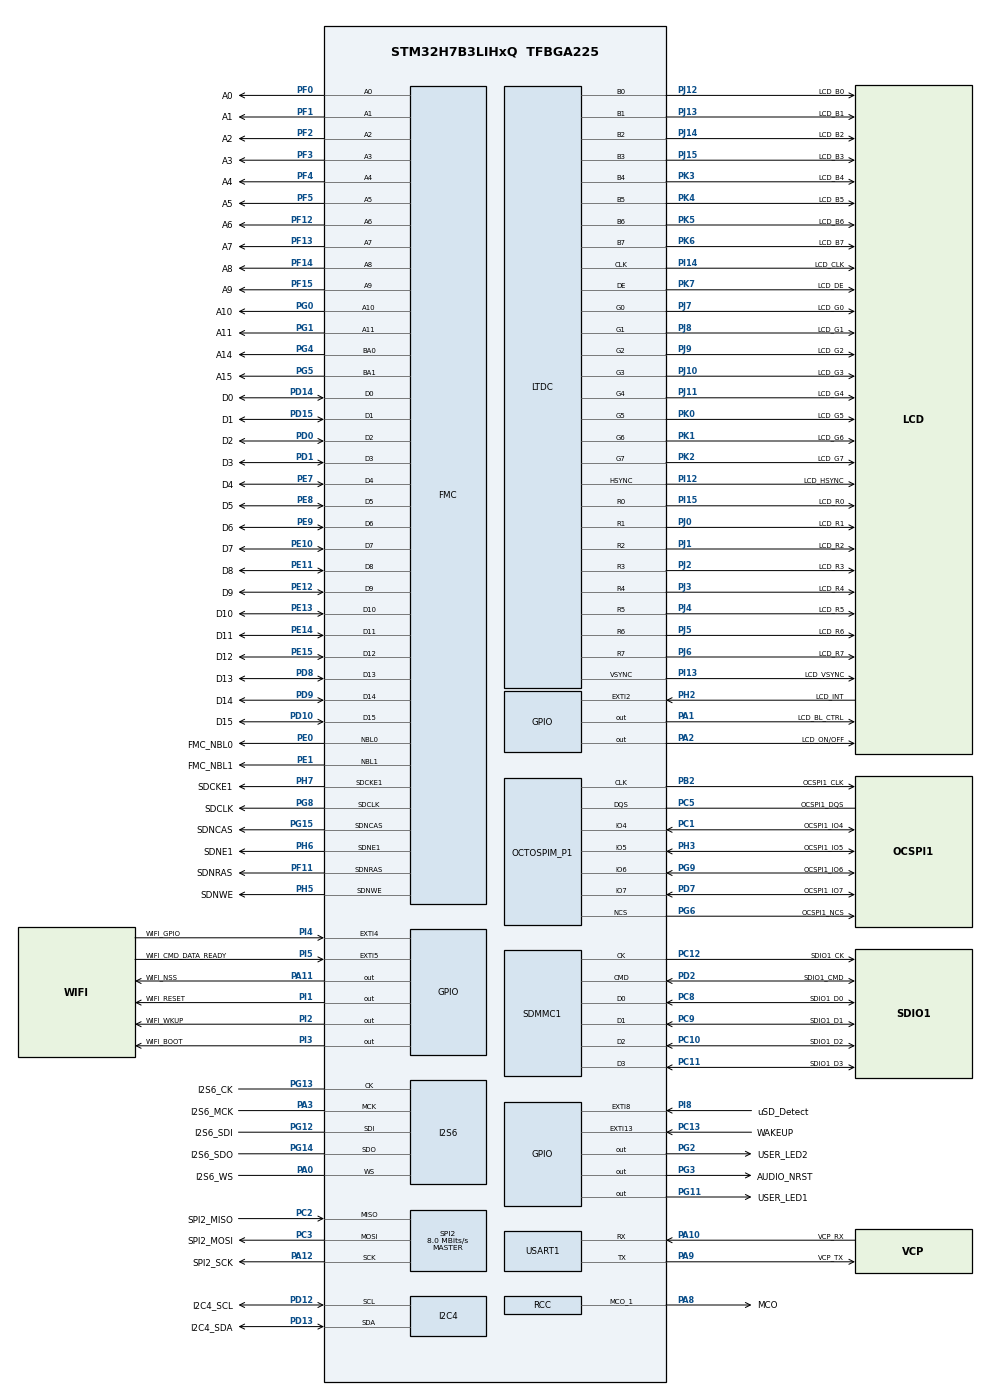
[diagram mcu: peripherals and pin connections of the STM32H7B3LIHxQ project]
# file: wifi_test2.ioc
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I2C4.Timing=0xC010151E
I2S6.ErrorAudioFreq=0.52 %
I2S6.FullDuplexMode=I2S_MODE_MASTER_FD
I2S6.Instance=SPI$Index
I2S6.RealAudioFreq=8.042 KHz
I2S6.VirtualMode=I2S_MODE_MASTER
LTDC.ActiveH=272
LTDC.ActiveW=480
LTDC.HBP=43
LTDC.HFP=8
LTDC.HSync=1
LTDC.VBP=12
LTDC.VFP=4
LTDC.VSync=10
Mcu.Family=STM32H7
Mcu.Name=STM32H7B3LIHxQ
Mcu.Package=TFBGA225
NVIC.PriorityGroup=NVIC_PRIORITYGROUP_4
OCTOSPI1.MemoryType=HAL_OSPI_MEMTYPE_MACRONIX
PA0.GPIO_Label=I2S6_WS
PA0.Mode=Full_Duplex_Master
PA0.Signal=I2S6_WS
PA1.GPIO_Label=LCD_BL_CTRL
PA1.PinState=GPIO_PIN_SET
PA1.Signal=GPIO_Output
PA10.GPIO_Label=VCP_RX
PA10.Mode=Asynchronous
PA10.Signal=USART1_RX
PA11.GPIO_Label=WIFI_NSS
PA11.Signal=GPIO_Output
PA12.GPIO_Label=SPI2_SCK
PA12.Mode=Full_Duplex_Master
PA12.Signal=SPI2_SCK
PA13.GPIO_Label=JTMS
PA13.Mode=JTAG_4_pins
PA13.Signal=DEBUG_JTMS-SWDIO
PA14.GPIO_Label=JTCK
PA14.Mode=JTAG_4_pins
PA14.Signal=DEBUG_JTCK-SWCLK
PA15.GPIO_Label=JTDI
PA15.Mode=JTAG_4_pins
PA15.Signal=DEBUG_JTDI
PA2.GPIO_Label=LCD_ON/OFF
PA2.PinState=GPIO_PIN_SET
PA2.Signal=GPIO_Output
PA3.GPIO_Label=I2S6_MCK
PA3.Mode=Master_Clock_Activated
PA3.Signal=I2S6_MCK
PA8.GPIO_Label=MCO
PA8.Mode=Clock-out-1
PA8.Signal=RCC_MCO_1
PA9.GPIO_Label=VCP_TX
PA9.Mode=Asynchronous
PA9.Signal=USART1_TX
PB2.GPIO_Label=OCSPI1_CLK
PB2.Mode=O1_P1_CLK
PB2.Signal=OCTOSPIM_P1_CLK
PB3.GPIO_Label=JTDO_TRACESWO
PB3.Mode=JTAG_4_pins
PB3.Signal=DEBUG_JTDO-SWO
PB4.Signal=DEBUG_JTRST
PC1.GPIO_Label=OCSPI1_IO4
PC1.Mode=OCTOSPI1_IOL_Port1H
PC1.Signal=OCTOSPIM_P1_IO4
PC10.GPIO_Label=SDIO1_D2
PC10.Mode=SD_4_bits_Wide_bus
PC10.Signal=SDMMC1_D2
PC11.GPIO_Label=SDIO1_D3
PC11.Mode=SD_4_bits_Wide_bus
PC11.Signal=SDMMC1_D3
PC12.GPIO_Label=SDIO1_CK
PC12.Mode=SD_4_bits_Wide_bus
PC12.Signal=SDMMC1_CK
PC13.GPIO_Label=WAKEUP
PC13.Signal=GPXTI13
PC14-OSC32_IN.Mode=LSE-External-Oscillator
PC14-OSC32_IN.Signal=RCC_OSC32_IN
PC15-OSC32_OUT.Mode=LSE-External-Oscillator
PC15-OSC32_OUT.Signal=RCC_OSC32_OUT
PC2.GPIO_Label=SPI2_MISO
PC2.Mode=Full_Duplex_Master
PC2.Signal=SPI2_MISO
PC3.GPIO_Label=SPI2_MOSI
PC3.Mode=Full_Duplex_Master
PC3.Signal=SPI2_MOSI
PC5.GPIO_Label=OCSPI1_DQS
PC5.Mode=OCTOSPI1_Port1_DQS
PC5.Signal=OCTOSPIM_P1_DQS
PC8.GPIO_Label=SDIO1_D0
PC8.Mode=SD_4_bits_Wide_bus
PC8.Signal=SDMMC1_D0
PC9.GPIO_Label=SDIO1_D1
PC9.Mode=SD_4_bits_Wide_bus
PC9.Signal=SDMMC1_D1
PD0.GPIO_Label=D2
PD0.Signal=FMC_D2_DA2
PD1.GPIO_Label=D3
PD1.Signal=FMC_D3_DA3
PD10.GPIO_Label=D15
PD10.Signal=FMC_D15_DA15
PD12.GPIO_Label=I2C4_SCL
PD12.GPIO_Pu=GPIO_PULLUP
PD12.Mode=I2C
PD12.Signal=I2C4_SCL
PD13.GPIO_Label=I2C4_SDA
PD13.GPIO_Pu=GPIO_PULLUP
PD13.Mode=I2C
PD13.Signal=I2C4_SDA
PD14.GPIO_Label=D0
PD14.Signal=FMC_D0_DA0
PD15.GPIO_Label=D1
PD15.Signal=FMC_D1_DA1
PD2.GPIO_Label=SDIO1_CMD
PD2.Mode=SD_4_bits_Wide_bus
PD2.Signal=SDMMC1_CMD
PD7.GPIO_Label=OCSPI1_IO7
PD7.Mode=OCTOSPI1_IOL_Port1H
PD7.Signal=OCTOSPIM_P1_IO7
PD8.GPIO_Label=D13
PD8.Signal=FMC_D13_DA13
PD9.GPIO_Label=D14
PD9.Signal=FMC_D14_DA14
PE0.GPIO_Label=FMC_NBL0
PE0.Signal=FMC_NBL0
PE1.GPIO_Label=FMC_NBL1
PE1.Signal=FMC_NBL1
PE10.GPIO_Label=D7
PE10.Signal=FMC_D7_DA7
PE11.GPIO_Label=D8
PE11.Signal=FMC_D8_DA8
PE12.GPIO_Label=D9
PE12.Signal=FMC_D9_DA9
PE13.GPIO_Label=D10
PE13.Signal=FMC_D10_DA10
PE14.GPIO_Label=D11
PE14.Signal=FMC_D11_DA11
PE15.GPIO_Label=D12
PE15.Signal=FMC_D12_DA12
PE7.GPIO_Label=D4
PE7.Signal=FMC_D4_DA4
PE8.GPIO_Label=D5
PE8.Signal=FMC_D5_DA5
PE9.GPIO_Label=D6
PE9.Signal=FMC_D6_DA6
PF0.GPIO_Label=A0
PF0.Signal=FMC_A0
PF1.GPIO_Label=A1
PF1.Signal=FMC_A1
PF11.GPIO_Label=SDNRAS
PF11.Signal=FMC_SDNRAS
PF12.GPIO_Label=A6
PF12.Signal=FMC_A6
PF13.GPIO_Label=A7
PF13.Signal=FMC_A7
PF14.GPIO_Label=A8
PF14.Signal=FMC_A8
PF15.GPIO_Label=A9
PF15.Signal=FMC_A9
PF2.GPIO_Label=A2
PF2.Signal=FMC_A2
PF3.GPIO_Label=A3
PF3.Signal=FMC_A3
PF4.GPIO_Label=A4
PF4.Signal=FMC_A4
PF5.GPIO_Label=A5
PF5.Signal=FMC_A5
PG0.GPIO_Label=A10
PG0.Signal=FMC_A10
PG1.GPIO_Label=A11
PG1.Signal=FMC_A11
PG11.GPIO_Label=USER_LED1
PG11.Signal=GPIO_Output
PG12.GPIO_Label=I2S6_SDI
PG12.Mode=Full_Duplex_Master
PG12.Signal=I2S6_SDI
PG13.GPIO_Label=I2S6_CK
PG13.Mode=Full_Duplex_Master
PG13.Signal=I2S6_CK
PG14.GPIO_Label=I2S6_SDO
PG14.Mode=Full_Duplex_Master
PG14.Signal=I2S6_SDO
PG15.GPIO_Label=SDNCAS
PG15.Signal=FMC_SDNCAS
PG2.GPIO_Label=USER_LED2
PG2.Signal=GPIO_Output
PG3.GPIO_Label=AUDIO_NRST
PG3.PinState=GPIO_PIN_SET
PG3.Signal=GPIO_Output
PG4.GPIO_Label=A14
PG4.Signal=FMC_A14_BA0
PG5.GPIO_Label=A15
PG5.Signal=FMC_A15_BA1
PG6.GPIO_Label=OCSPI1_NCS
PG6.Mode=OCTOSPI1_Port1_NCS
PG6.Signal=OCTOSPIM_P1_NCS
PG8.GPIO_Label=SDCLK
PG8.Signal=FMC_SDCLK
PG9.GPIO_Label=OCSPI1_IO6
PG9.Mode=OCTOSPI1_IOL_Port1H
PG9.Signal=OCTOSPIM_P1_IO6
PH0-OSC_IN.Mode=HSE-External-Oscillator
PH0-OSC_IN.Signal=RCC_OSC_IN
PH1-OSC_OUT.Mode=HSE-External-Oscillator
PH1-OSC_OUT.Signal=RCC_OSC_OUT
PH2.GPIO_Label=LCD_INT
PH2.Signal=GPXTI2
PH3.GPIO_Label=OCSPI1_IO5
PH3.Mode=OCTOSPI1_IOL_Port1H
PH3.Signal=OCTOSPIM_P1_IO5
PH5.GPIO_Label=SDNWE
PH5.Signal=FMC_SDNWE
PH6.GPIO_Label=SDNE1
PH6.Mode=SdramChipSelect2_1
PH6.Signal=FMC_SDNE1
PH7.GPIO_Label=SDCKE1
PH7.Mode=SdramChipSelect2_1
PH7.Signal=FMC_SDCKE1
PI1.GPIO_Label=WIFI_RESET
PI1.Signal=GPIO_Output
PI12.GPIO_Label=LCD_HSYNC
PI12.Mode=RGB888
PI12.Signal=LTDC_HSYNC
PI13.GPIO_Label=LCD_VSYNC
PI13.Mode=RGB888
PI13.Signal=LTDC_VSYNC
PI14.GPIO_Label=LCD_CLK
PI14.Mode=RGB888
PI14.Signal=LTDC_CLK
PI15.GPIO_Label=LCD_R0
PI15.Mode=RGB888
PI15.Signal=LTDC_R0
PI2.GPIO_Label=WIFI_WKUP
PI2.Signal=GPIO_Output
PI3.GPIO_Label=WIFI_BOOT
PI3.Signal=GPIO_Output
PI4.GPIO_Label=WIFI_GPIO
PI4.Signal=GPXTI4
PI5.GPIO_Label=WIFI_CMD_DATA_READY
PI5.Signal=GPXTI5
PI8.GPIO_Label=uSD_Detect
PI8.GPIO_PuPd=GPIO_PULLUP
PI8.Signal=GPXTI8
PJ0.GPIO_Label=LCD_R1
PJ0.Mode=RGB888
PJ0.Signal=LTDC_R1
PJ1.GPIO_Label=LCD_R2
PJ1.Mode=RGB888
PJ1.Signal=LTDC_R2
PJ10.GPIO_Label=LCD_G3
PJ10.Mode=RGB888
PJ10.Signal=LTDC_G3
PJ11.GPIO_Label=LCD_G4
PJ11.Mode=RGB888
PJ11.Signal=LTDC_G4
PJ12.GPIO_Label=LCD_B0
PJ12.Mode=RGB888
PJ12.Signal=LTDC_B0
PJ13.GPIO_Label=LCD_B1
PJ13.Mode=RGB888
PJ13.Signal=LTDC_B1
PJ14.GPIO_Label=LCD_B2
PJ14.Mode=RGB888
PJ14.Signal=LTDC_B2
PJ15.GPIO_Label=LCD_B3
PJ15.Mode=RGB888
PJ15.Signal=LTDC_B3
PJ2.GPIO_Label=LCD_R3
PJ2.Mode=RGB888
PJ2.Signal=LTDC_R3
PJ3.GPIO_Label=LCD_R4
PJ3.Mode=RGB888
PJ3.Signal=LTDC_R4
PJ4.GPIO_Label=LCD_R5
PJ4.Mode=RGB888
PJ4.Signal=LTDC_R5
PJ5.GPIO_Label=LCD_R6
PJ5.Mode=RGB888
PJ5.Signal=LTDC_R6
PJ6.GPIO_Label=LCD_R7
PJ6.Mode=RGB888
PJ6.Signal=LTDC_R7
PJ7.GPIO_Label=LCD_G0
PJ7.Mode=RGB888
PJ7.Signal=LTDC_G0
PJ8.GPIO_Label=LCD_G1
PJ8.Mode=RGB888
PJ8.Signal=LTDC_G1
PJ9.GPIO_Label=LCD_G2
PJ9.Mode=RGB888
PJ9.Signal=LTDC_G2
PK0.GPIO_Label=LCD_G5
PK0.Mode=RGB888
PK0.Signal=LTDC_G5
PK1.GPIO_Label=LCD_G6
PK1.Mode=RGB888
PK1.Signal=LTDC_G6
PK2.GPIO_Label=LCD_G7
PK2.Mode=RGB888
PK2.Signal=LTDC_G7
PK3.GPIO_Label=LCD_B4
PK3.Mode=RGB888
PK3.Signal=LTDC_B4
PK4.GPIO_Label=LCD_B5
PK4.Mode=RGB888
PK4.Signal=LTDC_B5
PK5.GPIO_Label=LCD_B6
PK5.Mode=RGB888
PK5.Signal=LTDC_B6
PK6.GPIO_Label=LCD_B7
PK6.Mode=RGB888
PK6.Signal=LTDC_B7
PK7.GPIO_Label=LCD_DE
PK7.Mode=RGB888
PK7.Signal=LTDC_DE
ProjectManager.HeapSize=0x200
ProjectManager.StackSize=0x400
ProjectManager.TargetToolchain=STM32CubeIDE
RCC.ADCFreq_Value=200000000
RCC.APB1Freq_Value=70000000
RCC.APB2Freq_Value=70000000
RCC.APB3Freq_Value=70000000
RCC.APB4Freq_Value=70000000
RCC.CDPPRE=RCC_APB3_DIV2
RCC.CDPPRE1=RCC_APB1_DIV2
RCC.CDPPRE2=RCC_APB2_DIV2
RCC.CortexFreq_Value=280000000
RCC.DIVM1=12
RCC.DIVM2=12
RCC.DIVM3=24
RCC.DIVN1=280
RCC.DIVN2=200
RCC.DIVN3=192
RCC.DIVP3=17
RCC.DIVQ1=3
RCC.DIVR1=4
RCC.DIVR2=4
RCC.FMCCLockSelection=RCC_FMCCLKSOURCE_PLL2
RCC.HCLKFreq_Value=140000000
RCC.HPRE=RCC_HCLK_DIV2
RCC.PLL2FRACN=0
RCC.PLL3FRACN=0
RCC.PLLFRACN=0
RCC.PLLSourceVirtual=RCC_PLLSOURCE_HSE
RCC.PWR_Regulator_Voltage_Scale=PWR_REGULATOR_VOLTAGE_SCALE0
RCC.QSPICLockSelection=RCC_OSPICLKSOURCE_PLL2
RCC.RCC_MCO1Source=RCC_MCO1SOURCE_HSE
RCC.RTCClockSelection=RCC_RTCCLKSOURCE_LSE
RCC.SDMMC1CLockSelection=RCC_SDMMCCLKSOURCE_PLL2
RCC.SPI123CLockSelection=RCC_SPI123CLKSOURCE_CLKP
RCC.SRDPPRE=RCC_APB4_DIV2
RCC.SYSCLKFreq_VALUE=280000000
RCC.SYSCLKSource=RCC_SYSCLKSOURCE_PLLCLK
RCC.SupplySource=PWR_DIRECT_SMPS_SUPPLY
RCC.USBFreq_Value=186666666.66666666
SH.FMC_A0.0=FMC_A0,12b-sda1
SH.FMC_A1.0=FMC_A1,12b-sda1
SH.FMC_A10.0=FMC_A10,12b-sda1
SH.FMC_A11.0=FMC_A11,12b-sda1
SH.FMC_A14_BA0.0=FMC_BA0,FourSdramBanks1
SH.FMC_A15_BA1.0=FMC_BA1,FourSdramBanks1
SH.FMC_A2.0=FMC_A2,12b-sda1
SH.FMC_A3.0=FMC_A3,12b-sda1
SH.FMC_A4.0=FMC_A4,12b-sda1
SH.FMC_A5.0=FMC_A5,12b-sda1
SH.FMC_A6.0=FMC_A6,12b-sda1
SH.FMC_A7.0=FMC_A7,12b-sda1
SH.FMC_A8.0=FMC_A8,12b-sda1
SH.FMC_A9.0=FMC_A9,12b-sda1
SH.FMC_D0_DA0.0=FMC_D0,sd-16b-d1
SH.FMC_D10_DA10.0=FMC_D10,sd-16b-d1
SH.FMC_D11_DA11.0=FMC_D11,sd-16b-d1
SH.FMC_D12_DA12.0=FMC_D12,sd-16b-d1
SH.FMC_D13_DA13.0=FMC_D13,sd-16b-d1
SH.FMC_D14_DA14.0=FMC_D14,sd-16b-d1
SH.FMC_D15_DA15.0=FMC_D15,sd-16b-d1
SH.FMC_D1_DA1.0=FMC_D1,sd-16b-d1
SH.FMC_D2_DA2.0=FMC_D2,sd-16b-d1
SH.FMC_D3_DA3.0=FMC_D3,sd-16b-d1
SH.FMC_D4_DA4.0=FMC_D4,sd-16b-d1
SH.FMC_D5_DA5.0=FMC_D5,sd-16b-d1
SH.FMC_D6_DA6.0=FMC_D6,sd-16b-d1
SH.FMC_D7_DA7.0=FMC_D7,sd-16b-d1
SH.FMC_D8_DA8.0=FMC_D8,sd-16b-d1
SH.FMC_D9_DA9.0=FMC_D9,sd-16b-d1
SH.FMC_NBL0.0=FMC_NBL0,Sd2ByteEnable1
SH.FMC_NBL1.0=FMC_NBL1,Sd2ByteEnable1
SH.FMC_SDCLK.0=FMC_SDCLK,12b-sda1
SH.FMC_SDNCAS.0=FMC_SDNCAS,12b-sda1
SH.FMC_SDNRAS.0=FMC_SDNRAS,12b-sda1
SH.FMC_SDNWE.0=FMC_SDNWE,12b-sda1
SPI2.BaudRatePrescaler=SPI_BAUDRATEPRESCALER_8
SPI2.CalculateBaudRate=8.0 MBits/s
SPI2.DataSize=SPI_DATASIZE_16BIT
SPI2.Direction=SPI_DIRECTION_2LINES
SPI2.Mode=SPI_MODE_MASTER
SPI2.VirtualType=VM_MASTER
USART1.VirtualMode-Asynchronous=VM_ASYNC
VP_MEMORYMAP_VS_MEMORYMAP.Mode=CurAppReg
VP_OCTOSPI1_VS_octo.Mode=octo_mode
VP_RTC_VS_RTC_Activate.Mode=RTC_Enabled
board=STM32H7B3I-DK

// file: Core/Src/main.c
/* USER CODE BEGIN Header */
/**
  ******************************************************************************
  * @file           : main.c
  * @brief          : Main program body
  ******************************************************************************
  * @attention
  *
  * Copyright (c) 2025 STMicroelectronics.
  * All rights reserved.
  *
  * This software is licensed under terms that can be found in the LICENSE file
  * in the root directory of this software component.
  * If no LICENSE file comes with this software, it is provided AS-IS.
  *
  ******************************************************************************
  */
/* USER CODE END Header */
#include "main.h"

/* USER CODE BEGIN Includes */
#include "wifi.h"
/* USER CODE END Includes */

/* USER CODE BEGIN PTD */
WIFI_HandleTypeDef hwifi;

char ssid[] = "test";
char passphrase[] = "password";

__IO FlagStatus cmdDataReady = 0;
static void WIFI_Init_main(void);
/* USER CODE END PTD */

I2C_HandleTypeDef hi2c4;

I2S_HandleTypeDef hi2s6;

LTDC_HandleTypeDef hltdc;

OSPI_HandleTypeDef hospi1;

RTC_HandleTypeDef hrtc;

SD_HandleTypeDef hsd1;

SPI_HandleTypeDef hspi2;

UART_HandleTypeDef huart1;

SDRAM_HandleTypeDef hsdram1;

void SystemClock_Config(void);
void PeriphCommonClock_Config(void);
static void MX_GPIO_Init(void);
static void MX_FMC_Init(void);
static void MX_I2C4_Init(void);
static void MX_I2S6_Init(void);
static void MX_LTDC_Init(void);
static void MX_OCTOSPI1_Init(void);
static void MX_RTC_Init(void);
static void MX_SDMMC1_SD_Init(void);
static void MX_SPI2_Init(void);
static void MX_USART1_UART_Init(void);

/* USER CODE BEGIN 0 */

static void WIFI_Init_main(){

	hwifi.handle = &hspi2;
	hwifi.ssid = ssid;
	hwifi.passphrase = passphrase;
	hwifi.securityType = WPA;
	hwifi.DHCP = SET;
	hwifi.ipStatus = IP_V4;
	hwifi.transportProtocol = WIFI_TCP_PROTOCOL;
	hwifi.port = 8080;
	WIFI_StatusTypeDef result;

	result = WIFI_Init(&hwifi);
	printf("%d",(uint8_t)result);
}

void HAL_GPIO_EXTI_Callback(uint16_t GPIO_Pin){

	if(GPIO_Pin == WIFI_CMD_DATA_READY_Pin){
		cmdDataReady = HAL_GPIO_ReadPin(WIFI_CMD_DATA_READY_GPIO_Port, WIFI_CMD_DATA_READY_Pin);
	}
}

void UART_DebugPrint(const char* message) {
    HAL_UART_Transmit(&huart1, (uint8_t*)message, strlen(message), 100);
    HAL_UART_Transmit(&huart1, (uint8_t*)"---", 2, 100);
}

/* USER CODE END 0 */

int main(void)
{

  /* MCU Configuration--------------------------------------------------------*/

  /* Reset of all peripherals, Initializes the Flash interface and the Systick. */
  HAL_Init();

  /* Configure the system clock */
  SystemClock_Config();

  /* Configure the peripherals common clocks */
  PeriphCommonClock_Config();

  /* Initialize all configured peripherals */
  MX_GPIO_Init();
  MX_FMC_Init();
  MX_I2C4_Init();
  MX_I2S6_Init();
  MX_LTDC_Init();
  MX_OCTOSPI1_Init();
  MX_RTC_Init();
  MX_SDMMC1_SD_Init();
  MX_SPI2_Init();
  MX_USART1_UART_Init();
  /* USER CODE BEGIN 2 */
  WIFI_Init_main();

  WIFI_JoinNetwork(&hwifi);
  /* USER CODE END 2 */

  /* Infinite loop */
  while (1)
  {

  }
}

void SystemClock_Config(void)
{
  RCC_OscInitTypeDef RCC_OscInitStruct = {0};
  RCC_ClkInitTypeDef RCC_ClkInitStruct = {0};

  /*AXI clock gating */
  RCC->CKGAENR = 0xFFFFFFFF;

  /** Supply configuration update enable
  */
  HAL_PWREx_ConfigSupply(PWR_DIRECT_SMPS_SUPPLY);

  /** Configure the main internal regulator output voltage
  */
  __HAL_PWR_VOLTAGESCALING_CONFIG(PWR_REGULATOR_VOLTAGE_SCALE0);

  while(!__HAL_PWR_GET_FLAG(PWR_FLAG_VOSRDY)) {}

  /** Configure LSE Drive Capability
  */
  HAL_PWR_EnableBkUpAccess();
  __HAL_RCC_LSEDRIVE_CONFIG(RCC_LSEDRIVE_LOW);

  /** Initializes the RCC Oscillators according to the specified parameters
  * in the RCC_OscInitTypeDef structure.
  */
  RCC_OscInitStruct.OscillatorType = RCC_OSCILLATORTYPE_HSI|RCC_OSCILLATORTYPE_HSE
                              |RCC_OSCILLATORTYPE_LSE;
  RCC_OscInitStruct.HSEState = RCC_HSE_ON;
  RCC_OscInitStruct.LSEState = RCC_LSE_ON;
  RCC_OscInitStruct.HSIState = RCC_HSI_DIV1;
  RCC_OscInitStruct.HSICalibrationValue = 64;
  RCC_OscInitStruct.PLL.PLLState = RCC_PLL_ON;
  RCC_OscInitStruct.PLL.PLLSource = RCC_PLLSOURCE_HSE;
  RCC_OscInitStruct.PLL.PLLM = 12;
  RCC_OscInitStruct.PLL.PLLN = 280;
  RCC_OscInitStruct.PLL.PLLP = 2;
  RCC_OscInitStruct.PLL.PLLQ = 3;
  RCC_OscInitStruct.PLL.PLLR = 4;
  RCC_OscInitStruct.PLL.PLLRGE = RCC_PLL1VCIRANGE_1;
  RCC_OscInitStruct.PLL.PLLVCOSEL = RCC_PLL1VCOWIDE;
  RCC_OscInitStruct.PLL.PLLFRACN = 0;
  if (HAL_RCC_OscConfig(&RCC_OscInitStruct) != HAL_OK)
  {
    Error_Handler();
  }

  /** Initializes the CPU, AHB and APB buses clocks
  */
  RCC_ClkInitStruct.ClockType = RCC_CLOCKTYPE_HCLK|RCC_CLOCKTYPE_SYSCLK
                              |RCC_CLOCKTYPE_PCLK1|RCC_CLOCKTYPE_PCLK2
                              |RCC_CLOCKTYPE_D3PCLK1|RCC_CLOCKTYPE_D1PCLK1;
  RCC_ClkInitStruct.SYSCLKSource = RCC_SYSCLKSOURCE_PLLCLK;
  RCC_ClkInitStruct.SYSCLKDivider = RCC_SYSCLK_DIV1;
  RCC_ClkInitStruct.AHBCLKDivider = RCC_HCLK_DIV2;
  RCC_ClkInitStruct.APB3CLKDivider = RCC_APB3_DIV2;
  RCC_ClkInitStruct.APB1CLKDivider = RCC_APB1_DIV2;
  RCC_ClkInitStruct.APB2CLKDivider = RCC_APB2_DIV2;
  RCC_ClkInitStruct.APB4CLKDivider = RCC_APB4_DIV2;

  if (HAL_RCC_ClockConfig(&RCC_ClkInitStruct, FLASH_LATENCY_3) != HAL_OK)
  {
    Error_Handler();
  }
  HAL_RCC_MCOConfig(RCC_MCO1, RCC_MCO1SOURCE_HSE, RCC_MCODIV_1);
}

void PeriphCommonClock_Config(void)
{
  RCC_PeriphCLKInitTypeDef PeriphClkInitStruct = {0};

  /** Initializes the peripherals clock
  */
  PeriphClkInitStruct.PeriphClockSelection = RCC_PERIPHCLK_FMC|RCC_PERIPHCLK_OSPI
                              |RCC_PERIPHCLK_SDMMC|RCC_PERIPHCLK_CKPER;
  PeriphClkInitStruct.PLL2.PLL2M = 12;
  PeriphClkInitStruct.PLL2.PLL2N = 200;
  PeriphClkInitStruct.PLL2.PLL2P = 2;
  PeriphClkInitStruct.PLL2.PLL2Q = 2;
  PeriphClkInitStruct.PLL2.PLL2R = 4;
  PeriphClkInitStruct.PLL2.PLL2RGE = RCC_PLL2VCIRANGE_1;
  PeriphClkInitStruct.PLL2.PLL2VCOSEL = RCC_PLL2VCOWIDE;
  PeriphClkInitStruct.PLL2.PLL2FRACN = 0;
  PeriphClkInitStruct.FmcClockSelection = RCC_FMCCLKSOURCE_PLL2;
  PeriphClkInitStruct.OspiClockSelection = RCC_OSPICLKSOURCE_PLL2;
  PeriphClkInitStruct.SdmmcClockSelection = RCC_SDMMCCLKSOURCE_PLL2;
  PeriphClkInitStruct.CkperClockSelection = RCC_CLKPSOURCE_HSI;
  if (HAL_RCCEx_PeriphCLKConfig(&PeriphClkInitStruct) != HAL_OK)
  {
    Error_Handler();
  }
}

static void MX_I2C4_Init(void)
{

  hi2c4.Instance = I2C4;
  hi2c4.Init.Timing = 0xC010151E;
  hi2c4.Init.OwnAddress1 = 0;
  hi2c4.Init.AddressingMode = I2C_ADDRESSINGMODE_7BIT;
  hi2c4.Init.DualAddressMode = I2C_DUALADDRESS_DISABLE;
  hi2c4.Init.OwnAddress2 = 0;
  hi2c4.Init.OwnAddress2Masks = I2C_OA2_NOMASK;
  hi2c4.Init.GeneralCallMode = I2C_GENERALCALL_DISABLE;
  hi2c4.Init.NoStretchMode = I2C_NOSTRETCH_DISABLE;
  if (HAL_I2C_Init(&hi2c4) != HAL_OK)
  {
    Error_Handler();
  }

  /** Configure Analogue filter
  */
  if (HAL_I2CEx_ConfigAnalogFilter(&hi2c4, I2C_ANALOGFILTER_ENABLE) != HAL_OK)
  {
    Error_Handler();
  }

  /** Configure Digital filter
  */
  if (HAL_I2CEx_ConfigDigitalFilter(&hi2c4, 0) != HAL_OK)
  {
    Error_Handler();
  }

}

static void MX_I2S6_Init(void)
{

  hi2s6.Instance = SPI6;
  hi2s6.Init.Mode = I2S_MODE_MASTER_FULLDUPLEX;
  hi2s6.Init.Standard = I2S_STANDARD_PHILIPS;
  hi2s6.Init.DataFormat = I2S_DATAFORMAT_16B;
  hi2s6.Init.MCLKOutput = I2S_MCLKOUTPUT_ENABLE;
  hi2s6.Init.AudioFreq = I2S_AUDIOFREQ_8K;
  hi2s6.Init.CPOL = I2S_CPOL_LOW;
  hi2s6.Init.FirstBit = I2S_FIRSTBIT_MSB;
  hi2s6.Init.WSInversion = I2S_WS_INVERSION_DISABLE;
  hi2s6.Init.Data24BitAlignment = I2S_DATA_24BIT_ALIGNMENT_RIGHT;
  hi2s6.Init.MasterKeepIOState = I2S_MASTER_KEEP_IO_STATE_DISABLE;
  if (HAL_I2S_Init(&hi2s6) != HAL_OK)
  {
    Error_Handler();
  }

}

static void MX_LTDC_Init(void)
{

  LTDC_LayerCfgTypeDef pLayerCfg = {0};
  LTDC_LayerCfgTypeDef pLayerCfg1 = {0};

  hltdc.Instance = LTDC;
  hltdc.Init.HSPolarity = LTDC_HSPOLARITY_AL;
  hltdc.Init.VSPolarity = LTDC_VSPOLARITY_AL;
  hltdc.Init.DEPolarity = LTDC_DEPOLARITY_AL;
  hltdc.Init.PCPolarity = LTDC_PCPOLARITY_IPC;
  hltdc.Init.HorizontalSync = 0;
  hltdc.Init.VerticalSync = 9;
  hltdc.Init.AccumulatedHBP = 43;
  hltdc.Init.AccumulatedVBP = 21;
  hltdc.Init.AccumulatedActiveW = 523;
  hltdc.Init.AccumulatedActiveH = 293;
  hltdc.Init.TotalWidth = 531;
  hltdc.Init.TotalHeigh = 297;
  hltdc.Init.Backcolor.Blue = 0;
  hltdc.Init.Backcolor.Green = 0;
  hltdc.Init.Backcolor.Red = 0;
  if (HAL_LTDC_Init(&hltdc) != HAL_OK)
  {
    Error_Handler();
  }
  pLayerCfg.WindowX0 = 0;
  pLayerCfg.WindowX1 = 0;
  pLayerCfg.WindowY0 = 0;
  pLayerCfg.WindowY1 = 0;
  pLayerCfg.PixelFormat = LTDC_PIXEL_FORMAT_ARGB8888;
  pLayerCfg.Alpha = 0;
  pLayerCfg.Alpha0 = 0;
  pLayerCfg.BlendingFactor1 = LTDC_BLENDING_FACTOR1_CA;
  pLayerCfg.BlendingFactor2 = LTDC_BLENDING_FACTOR2_CA;
  pLayerCfg.FBStartAdress = 0;
  pLayerCfg.ImageWidth = 0;
  pLayerCfg.ImageHeight = 0;
  pLayerCfg.Backcolor.Blue = 0;
  pLayerCfg.Backcolor.Green = 0;
  pLayerCfg.Backcolor.Red = 0;
  if (HAL_LTDC_ConfigLayer(&hltdc, &pLayerCfg, 0) != HAL_OK)
  {
    Error_Handler();
  }
  pLayerCfg1.WindowX0 = 0;
  pLayerCfg1.WindowX1 = 0;
  pLayerCfg1.WindowY0 = 0;
  pLayerCfg1.WindowY1 = 0;
  pLayerCfg1.PixelFormat = LTDC_PIXEL_FORMAT_ARGB8888;
  pLayerCfg1.Alpha = 0;
  pLayerCfg1.Alpha0 = 0;
  pLayerCfg1.BlendingFactor1 = LTDC_BLENDING_FACTOR1_CA;
  pLayerCfg1.BlendingFactor2 = LTDC_BLENDING_FACTOR2_CA;
  pLayerCfg1.FBStartAdress = 0;
  pLayerCfg1.ImageWidth = 0;
  pLayerCfg1.ImageHeight = 0;
  pLayerCfg1.Backcolor.Blue = 0;
  pLayerCfg1.Backcolor.Green = 0;
  pLayerCfg1.Backcolor.Red = 0;
  if (HAL_LTDC_ConfigLayer(&hltdc, &pLayerCfg1, 1) != HAL_OK)
  {
    Error_Handler();
  }

}

static void MX_OCTOSPI1_Init(void)
{

  OSPIM_CfgTypeDef sOspiManagerCfg = {0};

  /* OCTOSPI1 parameter configuration*/
  hospi1.Instance = OCTOSPI1;
  hospi1.Init.FifoThreshold = 1;
  hospi1.Init.DualQuad = HAL_OSPI_DUALQUAD_DISABLE;
  hospi1.Init.MemoryType = HAL_OSPI_MEMTYPE_MACRONIX;
  hospi1.Init.DeviceSize = 32;
  hospi1.Init.ChipSelectHighTime = 1;
  hospi1.Init.FreeRunningClock = HAL_OSPI_FREERUNCLK_DISABLE;
  hospi1.Init.ClockMode = HAL_OSPI_CLOCK_MODE_0;
  hospi1.Init.WrapSize = HAL_OSPI_WRAP_NOT_SUPPORTED;
  hospi1.Init.ClockPrescaler = 1;
  hospi1.Init.SampleShifting = HAL_OSPI_SAMPLE_SHIFTING_NONE;
  hospi1.Init.DelayHoldQuarterCycle = HAL_OSPI_DHQC_DISABLE;
  hospi1.Init.ChipSelectBoundary = 0;
  hospi1.Init.DelayBlockBypass = HAL_OSPI_DELAY_BLOCK_BYPASSED;
  hospi1.Init.MaxTran = 0;
  hospi1.Init.Refresh = 0;
  if (HAL_OSPI_Init(&hospi1) != HAL_OK)
  {
    Error_Handler();
  }
  sOspiManagerCfg.ClkPort = 1;
  sOspiManagerCfg.DQSPort = 1;
  sOspiManagerCfg.NCSPort = 1;
  sOspiManagerCfg.IOLowPort = HAL_OSPIM_IOPORT_1_HIGH;
  if (HAL_OSPIM_Config(&hospi1, &sOspiManagerCfg, HAL_OSPI_TIMEOUT_DEFAULT_VALUE) != HAL_OK)
  {
    Error_Handler();
  }

}

static void MX_RTC_Init(void)
{

  /** Initialize RTC Only
  */
  hrtc.Instance = RTC;
  hrtc.Init.HourFormat = RTC_HOURFORMAT_24;
  hrtc.Init.AsynchPrediv = 127;
  hrtc.Init.SynchPrediv = 255;
  hrtc.Init.OutPut = RTC_OUTPUT_DISABLE;
  hrtc.Init.OutPutPolarity = RTC_OUTPUT_POLARITY_HIGH;
  hrtc.Init.OutPutType = RTC_OUTPUT_TYPE_OPENDRAIN;
  hrtc.Init.OutPutRemap = RTC_OUTPUT_REMAP_NONE;
  if (HAL_RTC_Init(&hrtc) != HAL_OK)
  {
    Error_Handler();
  }

}

static void MX_SDMMC1_SD_Init(void)
{

  hsd1.Instance = SDMMC1;
  hsd1.Init.ClockEdge = SDMMC_CLOCK_EDGE_RISING;
  hsd1.Init.ClockPowerSave = SDMMC_CLOCK_POWER_SAVE_DISABLE;
  hsd1.Init.BusWide = SDMMC_BUS_WIDE_4B;
  hsd1.Init.HardwareFlowControl = SDMMC_HARDWARE_FLOW_CONTROL_DISABLE;
  hsd1.Init.ClockDiv = 0;
  if (HAL_SD_Init(&hsd1) != HAL_OK)
  {
    Error_Handler();
  }

}

static void MX_SPI2_Init(void)
{

  /* SPI2 parameter configuration*/
  hspi2.Instance = SPI2;
  hspi2.Init.Mode = SPI_MODE_MASTER;
  hspi2.Init.Direction = SPI_DIRECTION_2LINES;
  hspi2.Init.DataSize = SPI_DATASIZE_16BIT;
  hspi2.Init.CLKPolarity = SPI_POLARITY_LOW;
  hspi2.Init.CLKPhase = SPI_PHASE_1EDGE;
  hspi2.Init.NSS = SPI_NSS_SOFT;
  hspi2.Init.BaudRatePrescaler = SPI_BAUDRATEPRESCALER_8;
  hspi2.Init.FirstBit = SPI_FIRSTBIT_MSB;
  hspi2.Init.TIMode = SPI_TIMODE_DISABLE;
  hspi2.Init.CRCCalculation = SPI_CRCCALCULATION_DISABLE;
  hspi2.Init.CRCPolynomial = 0x0;
  hspi2.Init.NSSPMode = SPI_NSS_PULSE_ENABLE;
  hspi2.Init.NSSPolarity = SPI_NSS_POLARITY_LOW;
  hspi2.Init.FifoThreshold = SPI_FIFO_THRESHOLD_01DATA;
  hspi2.Init.TxCRCInitializationPattern = SPI_CRC_INITIALIZATION_ALL_ZERO_PATTERN;
  hspi2.Init.RxCRCInitializationPattern = SPI_CRC_INITIALIZATION_ALL_ZERO_PATTERN;
  hspi2.Init.MasterSSIdleness = SPI_MASTER_SS_IDLENESS_00CYCLE;
  hspi2.Init.MasterInterDataIdleness = SPI_MASTER_INTERDATA_IDLENESS_00CYCLE;
  hspi2.Init.MasterReceiverAutoSusp = SPI_MASTER_RX_AUTOSUSP_DISABLE;
  hspi2.Init.MasterKeepIOState = SPI_MASTER_KEEP_IO_STATE_DISABLE;
  hspi2.Init.IOSwap = SPI_IO_SWAP_DISABLE;
  if (HAL_SPI_Init(&hspi2) != HAL_OK)
  {
    Error_Handler();
  }

}

static void MX_USART1_UART_Init(void)
{

  huart1.Instance = USART1;
  huart1.Init.BaudRate = 115200;
  huart1.Init.WordLength = UART_WORDLENGTH_8B;
  huart1.Init.StopBits = UART_STOPBITS_1;
  huart1.Init.Parity = UART_PARITY_NONE;
  huart1.Init.Mode = UART_MODE_TX_RX;
  huart1.Init.HwFlowCtl = UART_HWCONTROL_NONE;
  huart1.Init.OverSampling = UART_OVERSAMPLING_16;
  huart1.Init.OneBitSampling = UART_ONE_BIT_SAMPLE_DISABLE;
  huart1.Init.ClockPrescaler = UART_PRESCALER_DIV1;
  huart1.AdvancedInit.AdvFeatureInit = UART_ADVFEATURE_NO_INIT;
  if (HAL_UART_Init(&huart1) != HAL_OK)
  {
    Error_Handler();
  }
  if (HAL_UARTEx_SetTxFifoThreshold(&huart1, UART_TXFIFO_THRESHOLD_1_8) != HAL_OK)
  {
    Error_Handler();
  }
  if (HAL_UARTEx_SetRxFifoThreshold(&huart1, UART_RXFIFO_THRESHOLD_1_8) != HAL_OK)
  {
    Error_Handler();
  }
  if (HAL_UARTEx_DisableFifoMode(&huart1) != HAL_OK)
  {
    Error_Handler();
  }

}

/* FMC initialization function */
static void MX_FMC_Init(void)
{

  FMC_SDRAM_TimingTypeDef SdramTiming = {0};

  /** Perform the SDRAM1 memory initialization sequence
  */
  hsdram1.Instance = FMC_SDRAM_DEVICE;
  /* hsdram1.Init */
  hsdram1.Init.SDBank = FMC_SDRAM_BANK2;
  hsdram1.Init.ColumnBitsNumber = FMC_SDRAM_COLUMN_BITS_NUM_8;
  hsdram1.Init.RowBitsNumber = FMC_SDRAM_ROW_BITS_NUM_12;
  hsdram1.Init.MemoryDataWidth = FMC_SDRAM_MEM_BUS_WIDTH_16;
  hsdram1.Init.InternalBankNumber = FMC_SDRAM_INTERN_BANKS_NUM_4;
  hsdram1.Init.CASLatency = FMC_SDRAM_CAS_LATENCY_1;
  hsdram1.Init.WriteProtection = FMC_SDRAM_WRITE_PROTECTION_DISABLE;
  hsdram1.Init.SDClockPeriod = FMC_SDRAM_CLOCK_DISABLE;
  hsdram1.Init.ReadBurst = FMC_SDRAM_RBURST_DISABLE;
  hsdram1.Init.ReadPipeDelay = FMC_SDRAM_RPIPE_DELAY_0;
  /* SdramTiming */
  SdramTiming.LoadToActiveDelay = 16;
  SdramTiming.ExitSelfRefreshDelay = 16;
  SdramTiming.SelfRefreshTime = 16;
  SdramTiming.RowCycleDelay = 16;
  SdramTiming.WriteRecoveryTime = 16;
  SdramTiming.RPDelay = 16;
  SdramTiming.RCDDelay = 16;

  if (HAL_SDRAM_Init(&hsdram1, &SdramTiming) != HAL_OK)
  {
    Error_Handler( );
  }

}

static void MX_GPIO_Init(void)
{
  GPIO_InitTypeDef GPIO_InitStruct = {0};

  /* GPIO Ports Clock Enable */
  __HAL_RCC_GPIOI_CLK_ENABLE();
  __HAL_RCC_GPIOG_CLK_ENABLE();
  __HAL_RCC_GPIOK_CLK_ENABLE();
  __HAL_RCC_GPIOD_CLK_ENABLE();
  __HAL_RCC_GPIOC_CLK_ENABLE();
  __HAL_RCC_GPIOE_CLK_ENABLE();
  __HAL_RCC_GPIOB_CLK_ENABLE();
  __HAL_RCC_GPIOJ_CLK_ENABLE();
  __HAL_RCC_GPIOA_CLK_ENABLE();
  __HAL_RCC_GPIOF_CLK_ENABLE();
  __HAL_RCC_GPIOH_CLK_ENABLE();

  /*Configure GPIO pin Output Level */
  HAL_GPIO_WritePin(GPIOI, WIFI_BOOT_Pin|WIFI_WKUP_Pin|WIFI_RESET_Pin, GPIO_PIN_RESET);

  /*Configure GPIO pin Output Level */
  HAL_GPIO_WritePin(GPIOG, USER_LED1_Pin|USER_LED2_Pin, GPIO_PIN_RESET);

  /*Configure GPIO pin Output Level */
  HAL_GPIO_WritePin(WIFI_NSS_GPIO_Port, WIFI_NSS_Pin, GPIO_PIN_RESET);

  /*Configure GPIO pin Output Level */
  HAL_GPIO_WritePin(AUDIO_NRST_GPIO_Port, AUDIO_NRST_Pin, GPIO_PIN_SET);

  /*Configure GPIO pin Output Level */
  HAL_GPIO_WritePin(GPIOA, LCD_BL_CTRL_Pin|LCD_ON_OFF_Pin, GPIO_PIN_SET);

  /*Configure GPIO pins : WIFI_GPIO_Pin WIFI_CMD_DATA_READY_Pin */
  GPIO_InitStruct.Pin = WIFI_GPIO_Pin|WIFI_CMD_DATA_READY_Pin;
  GPIO_InitStruct.Mode = GPIO_MODE_IT_RISING;
  GPIO_InitStruct.Pull = GPIO_NOPULL;
  HAL_GPIO_Init(GPIOI, &GPIO_InitStruct);

  /*Configure GPIO pins : WIFI_BOOT_Pin WIFI_WKUP_Pin WIFI_RESET_Pin */
  GPIO_InitStruct.Pin = WIFI_BOOT_Pin|WIFI_WKUP_Pin|WIFI_RESET_Pin;
  GPIO_InitStruct.Mode = GPIO_MODE_OUTPUT_PP;
  GPIO_InitStruct.Pull = GPIO_NOPULL;
  GPIO_InitStruct.Speed = GPIO_SPEED_FREQ_LOW;
  HAL_GPIO_Init(GPIOI, &GPIO_InitStruct);

  /*Configure GPIO pins : USER_LED1_Pin AUDIO_NRST_Pin USER_LED2_Pin */
  GPIO_InitStruct.Pin = USER_LED1_Pin|AUDIO_NRST_Pin|USER_LED2_Pin;
  GPIO_InitStruct.Mode = GPIO_MODE_OUTPUT_PP;
  GPIO_InitStruct.Pull = GPIO_NOPULL;
  GPIO_InitStruct.Speed = GPIO_SPEED_FREQ_LOW;
  HAL_GPIO_Init(GPIOG, &GPIO_InitStruct);

  /*Configure GPIO pin : uSD_Detect_Pin */
  GPIO_InitStruct.Pin = uSD_Detect_Pin;
  GPIO_InitStruct.Mode = GPIO_MODE_IT_RISING;
  GPIO_InitStruct.Pull = GPIO_PULLUP;
  HAL_GPIO_Init(uSD_Detect_GPIO_Port, &GPIO_InitStruct);

  /*Configure GPIO pins : WIFI_NSS_Pin LCD_BL_CTRL_Pin LCD_ON_OFF_Pin */
  GPIO_InitStruct.Pin = WIFI_NSS_Pin|LCD_BL_CTRL_Pin|LCD_ON_OFF_Pin;
  GPIO_InitStruct.Mode = GPIO_MODE_OUTPUT_PP;
  GPIO_InitStruct.Pull = GPIO_NOPULL;
  GPIO_InitStruct.Speed = GPIO_SPEED_FREQ_LOW;
  HAL_GPIO_Init(GPIOA, &GPIO_InitStruct);

  /*Configure GPIO pin : WAKEUP_Pin */
  GPIO_InitStruct.Pin = WAKEUP_Pin;
  GPIO_InitStruct.Mode = GPIO_MODE_IT_RISING;
  GPIO_InitStruct.Pull = GPIO_NOPULL;
  HAL_GPIO_Init(WAKEUP_GPIO_Port, &GPIO_InitStruct);

  /*Configure GPIO pin : MCO_Pin */
  GPIO_InitStruct.Pin = MCO_Pin;
  GPIO_InitStruct.Mode = GPIO_MODE_AF_PP;
  GPIO_InitStruct.Pull = GPIO_NOPULL;
  GPIO_InitStruct.Speed = GPIO_SPEED_FREQ_LOW;
  GPIO_InitStruct.Alternate = GPIO_AF0_MCO;
  HAL_GPIO_Init(MCO_GPIO_Port, &GPIO_InitStruct);

  /*Configure GPIO pin : LCD_INT_Pin */
  GPIO_InitStruct.Pin = LCD_INT_Pin;
  GPIO_InitStruct.Mode = GPIO_MODE_IT_RISING;
  GPIO_InitStruct.Pull = GPIO_NOPULL;
  HAL_GPIO_Init(LCD_INT_GPIO_Port, &GPIO_InitStruct);

}

void Error_Handler(void)
{
  __disable_irq();
  while (1)
  {
  }
}
